AUTOSAR XML (schema 4.0)
package /Powertrain
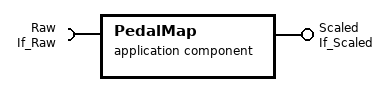
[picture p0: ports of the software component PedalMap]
  application sw component type PedalMap
    require port Raw: required-interface=If_Raw
    provide port Scaled: provided-interface=If_Scaled
